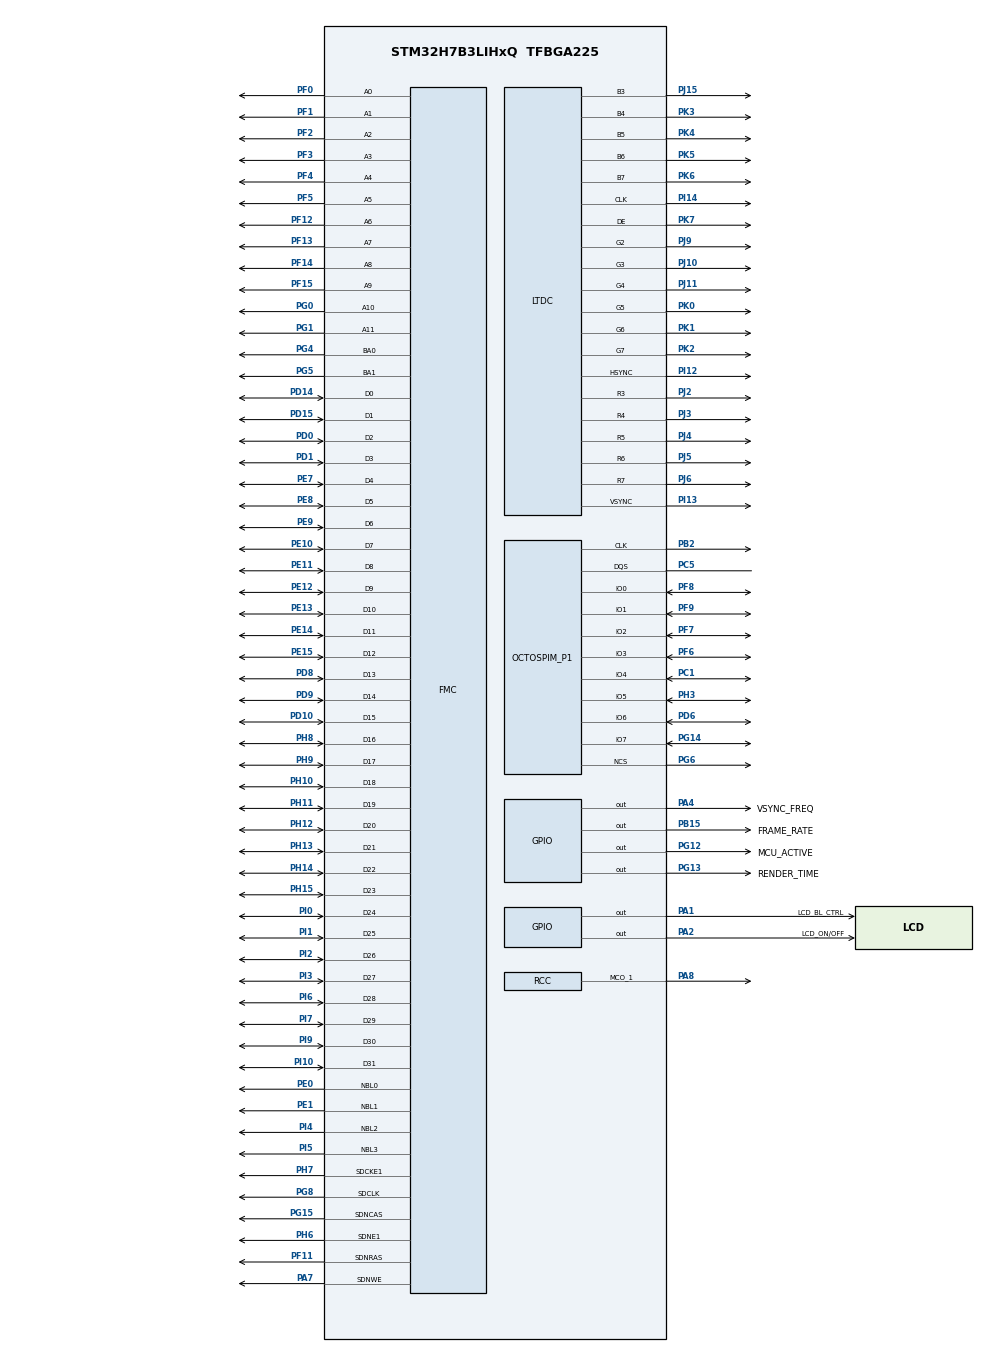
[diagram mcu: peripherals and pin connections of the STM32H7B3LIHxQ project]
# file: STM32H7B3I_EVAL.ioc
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CORTEX_M7.AccessPermission-Cortex_Memory_Protection_Unit_Region0_Settings=MPU_REGION_FULL_ACCESS
CORTEX_M7.AccessPermission-Cortex_Memory_Protection_Unit_Region1_Settings=MPU_REGION_NO_ACCESS
CORTEX_M7.AccessPermission-Cortex_Memory_Protection_Unit_Region2_Settings=MPU_REGION_FULL_ACCESS
CORTEX_M7.AccessPermission-Cortex_Memory_Protection_Unit_Region3_Settings=MPU_REGION_NO_ACCESS
CORTEX_M7.AccessPermission-Cortex_Memory_Protection_Unit_Region4_Settings=MPU_REGION_FULL_ACCESS
CORTEX_M7.BaseAddress-Cortex_Memory_Protection_Unit_Region0_Settings=0x24000000
CORTEX_M7.BaseAddress-Cortex_Memory_Protection_Unit_Region1_Settings=0x90000000
CORTEX_M7.BaseAddress-Cortex_Memory_Protection_Unit_Region2_Settings=0x90000000
CORTEX_M7.BaseAddress-Cortex_Memory_Protection_Unit_Region3_Settings=0xD0000000
CORTEX_M7.BaseAddress-Cortex_Memory_Protection_Unit_Region4_Settings=0xD0000000
CORTEX_M7.CPU_DCache=Enabled
CORTEX_M7.CPU_ICache=Enabled
CORTEX_M7.DisableExec-Cortex_Memory_Protection_Unit_Region0_Settings=MPU_INSTRUCTION_ACCESS_DISABLE
CORTEX_M7.DisableExec-Cortex_Memory_Protection_Unit_Region1_Settings=MPU_INSTRUCTION_ACCESS_DISABLE
CORTEX_M7.DisableExec-Cortex_Memory_Protection_Unit_Region2_Settings=MPU_INSTRUCTION_ACCESS_DISABLE
CORTEX_M7.DisableExec-Cortex_Memory_Protection_Unit_Region3_Settings=MPU_INSTRUCTION_ACCESS_DISABLE
CORTEX_M7.DisableExec-Cortex_Memory_Protection_Unit_Region4_Settings=MPU_INSTRUCTION_ACCESS_DISABLE
CORTEX_M7.Enable-Cortex_Memory_Protection_Unit_Region0_Settings=MPU_REGION_ENABLE
CORTEX_M7.Enable-Cortex_Memory_Protection_Unit_Region1_Settings=MPU_REGION_ENABLE
CORTEX_M7.Enable-Cortex_Memory_Protection_Unit_Region2_Settings=MPU_REGION_ENABLE
CORTEX_M7.Enable-Cortex_Memory_Protection_Unit_Region3_Settings=MPU_REGION_ENABLE
CORTEX_M7.Enable-Cortex_Memory_Protection_Unit_Region4_Settings=MPU_REGION_ENABLE
CORTEX_M7.IsBufferable-Cortex_Memory_Protection_Unit_Region2_Settings=MPU_ACCESS_NOT_BUFFERABLE
CORTEX_M7.IsBufferable-Cortex_Memory_Protection_Unit_Region4_Settings=MPU_ACCESS_BUFFERABLE
CORTEX_M7.IsCacheable-Cortex_Memory_Protection_Unit_Region0_Settings=MPU_ACCESS_CACHEABLE
CORTEX_M7.IsCacheable-Cortex_Memory_Protection_Unit_Region2_Settings=MPU_ACCESS_CACHEABLE
CORTEX_M7.IsCacheable-Cortex_Memory_Protection_Unit_Region4_Settings=MPU_ACCESS_CACHEABLE
CORTEX_M7.MPU_Control=MPU_PRIVILEGED_DEFAULT
CORTEX_M7.Size-Cortex_Memory_Protection_Unit_Region0_Settings=MPU_REGION_SIZE_1MB
CORTEX_M7.Size-Cortex_Memory_Protection_Unit_Region1_Settings=MPU_REGION_SIZE_512MB
CORTEX_M7.Size-Cortex_Memory_Protection_Unit_Region2_Settings=MPU_REGION_SIZE_64MB
CORTEX_M7.Size-Cortex_Memory_Protection_Unit_Region3_Settings=MPU_REGION_SIZE_512MB
CORTEX_M7.Size-Cortex_Memory_Protection_Unit_Region4_Settings=MPU_REGION_SIZE_32MB
DMA2D.ColorMode=DMA2D_OUTPUT_RGB565
DMA2D.Mode=DMA2D_R2M
FMC.CASLatency2=FMC_SDRAM_CAS_LATENCY_3
FMC.ColumnBitsNumber2=FMC_SDRAM_COLUMN_BITS_NUM_9
FMC.ExitSelfRefreshDelay2=7
FMC.LoadToActiveDelay2=2
FMC.RCDDelay2=2
FMC.RPDelay2=2
FMC.ReadBurst2=FMC_SDRAM_RBURST_ENABLE
FMC.ReadPipeDelay2=FMC_SDRAM_RPIPE_DELAY_2
FMC.RowCycleDelay2=7
FMC.SelfRefreshTime2=4
FMC.WriteRecoveryTime2=3
FREERTOS.Tasks01=defaultTask,24,128,StartDefaultTask,Default,NULL,Dynamic,NULL,NULL;TouchGFXTask,24,4096,TouchGFX_Task,As external,NULL,Dynamic,NULL,NULL
FREERTOS.configTOTAL_HEAP_SIZE=32768
FREERTOS.configUSE_APPLICATION_TASK_TAG=1
FREERTOS.configUSE_IDLE_HOOK=1
FREERTOS.configUSE_PREEMPTION=1
LTDC.ActiveW=800
LTDC.Alpha_L0=255
LTDC.BlendingFactor1_L0=LTDC_BLENDING_FACTOR1_CA
LTDC.BlendingFactor2_L0=LTDC_BLENDING_FACTOR2_CA
LTDC.Blue_L0=0
LTDC.HBP=2
LTDC.HFP=210
LTDC.HSync=46
LTDC.ImageHeight_L0=480
LTDC.ImageWidth_L0=800
LTDC.Layers=0
LTDC.PixelFormat_L0=LTDC_PIXEL_FORMAT_RGB565
LTDC.VBP=2
LTDC.VFP=22
LTDC.VSync=23
LTDC.WindowX1_L0=800
LTDC.WindowY1_L0=480
Mcu.Family=STM32H7
Mcu.Name=STM32H7B3LIHxQ
Mcu.Package=TFBGA225
NVIC.DMA2D_IRQn=true\:9\:0\:true\:false\:true\:true\:true\:true\:true
NVIC.LTDC_IRQn=true\:9\:0\:true\:false\:true\:true\:true\:true\:true
NVIC.OCTOSPI1_IRQn=true\:6\:0\:true\:false\:true\:true\:true\:true\:true
NVIC.PriorityGroup=NVIC_PRIORITYGROUP_4
NVIC.TIM6_DAC_IRQn=true\:0\:0\:false\:false\:true\:false\:false\:true\:true
NVIC.TimeBase=TIM6_DAC_IRQn
NVIC.TimeBaseIP=TIM6
OCTOSPI1.ChipSelectBoundary=0
OCTOSPI1.ChipSelectHighTime=2
OCTOSPI1.ClockPrescaler=3
OCTOSPI1.DelayHoldQuarterCycle=HAL_OSPI_DHQC_ENABLE
OCTOSPI1.FifoThreshold=4
OCTOSPI1.MemoryType=HAL_OSPI_MEMTYPE_MACRONIX
PA1.GPIO_Label=LCD_BL_CTRL
PA1.Signal=GPIO_Output
PA2.GPIO_Label=LCD_ON/OFF
PA2.Signal=GPIO_Output
PA4.GPIO_Label=VSYNC_FREQ
PA4.GPIO_Speed=GPIO_SPEED_FREQ_VERY_HIGH
PA4.Signal=GPIO_Output
PA7.Signal=FMC_SDNWE
PA8.Mode=Clock-out-1
PA8.Signal=RCC_MCO_1
PB15.GPIO_Label=FRAME_RATE
PB15.GPIO_Speed=GPIO_SPEED_FREQ_VERY_HIGH
PB15.Signal=GPIO_Output
PB2.Mode=O1_P1_CLK
PB2.Signal=OCTOSPIM_P1_CLK
PC1.Mode=OCTOSPI1_IOH_Port1H
PC1.Signal=OCTOSPIM_P1_IO4
PC5.Mode=OCTOSPI1_Port1_DQS
PC5.Signal=OCTOSPIM_P1_DQS
PD0.Signal=FMC_D2_DA2
PD1.Signal=FMC_D3_DA3
PD10.Signal=FMC_D15_DA15
PD14.Signal=FMC_D0_DA0
PD15.Signal=FMC_D1_DA1
PD6.Mode=OCTOSPI1_IOH_Port1H
PD6.Signal=OCTOSPIM_P1_IO6
PD8.Signal=FMC_D13_DA13
PD9.Signal=FMC_D14_DA14
PE0.Signal=FMC_NBL0
PE1.Signal=FMC_NBL1
PE10.Signal=FMC_D7_DA7
PE11.Signal=FMC_D8_DA8
PE12.Signal=FMC_D9_DA9
PE13.Signal=FMC_D10_DA10
PE14.Signal=FMC_D11_DA11
PE15.Signal=FMC_D12_DA12
PE7.Signal=FMC_D4_DA4
PE8.Signal=FMC_D5_DA5
PE9.Signal=FMC_D6_DA6
PF0.Signal=FMC_A0
PF1.Signal=FMC_A1
PF11.Signal=FMC_SDNRAS
PF12.Signal=FMC_A6
PF13.Signal=FMC_A7
PF14.Signal=FMC_A8
PF15.Signal=FMC_A9
PF2.Signal=FMC_A2
PF3.Signal=FMC_A3
PF4.Signal=FMC_A4
PF5.Signal=FMC_A5
PF6.Mode=OCTOSPI1_IOL_Port1L
PF6.Signal=OCTOSPIM_P1_IO3
PF7.Mode=OCTOSPI1_IOL_Port1L
PF7.Signal=OCTOSPIM_P1_IO2
PF8.Mode=OCTOSPI1_IOL_Port1L
PF8.Signal=OCTOSPIM_P1_IO0
PF9.Mode=OCTOSPI1_IOL_Port1L
PF9.Signal=OCTOSPIM_P1_IO1
PG0.Signal=FMC_A10
PG1.Signal=FMC_A11
PG12.GPIO_Label=MCU_ACTIVE
PG12.GPIO_Speed=GPIO_SPEED_FREQ_VERY_HIGH
PG12.Signal=GPIO_Output
PG13.GPIO_Label=RENDER_TIME
PG13.GPIO_Speed=GPIO_SPEED_FREQ_VERY_HIGH
PG13.Signal=GPIO_Output
PG14.Mode=OCTOSPI1_IOH_Port1H
PG14.Signal=OCTOSPIM_P1_IO7
PG15.Signal=FMC_SDNCAS
PG4.Signal=FMC_A14_BA0
PG5.Signal=FMC_A15_BA1
PG6.Mode=OCTOSPI1_Port1_NCS
PG6.Signal=OCTOSPIM_P1_NCS
PG8.Signal=FMC_SDCLK
PH0-OSC_IN.Mode=HSE-External-Oscillator
PH0-OSC_IN.Signal=RCC_OSC_IN
PH1-OSC_OUT.Mode=HSE-External-Oscillator
PH1-OSC_OUT.Signal=RCC_OSC_OUT
PH10.Signal=FMC_D18
PH11.Signal=FMC_D19
PH12.Signal=FMC_D20
PH13.Signal=FMC_D21
PH14.Signal=FMC_D22
PH15.Signal=FMC_D23
PH3.Mode=OCTOSPI1_IOH_Port1H
PH3.Signal=OCTOSPIM_P1_IO5
PH6.Mode=SdramChipSelect2_2
PH6.Signal=FMC_SDNE1
PH7.Mode=SdramChipSelect2_2
PH7.Signal=FMC_SDCKE1
PH8.Signal=FMC_D16
PH9.Signal=FMC_D17
PI0.Signal=FMC_D24
PI1.Signal=FMC_D25
PI10.Signal=FMC_D31
PI12.GPIO_Speed=GPIO_SPEED_FREQ_VERY_HIGH
PI12.Mode=RGB565
PI12.Signal=LTDC_HSYNC
PI13.GPIO_Speed=GPIO_SPEED_FREQ_VERY_HIGH
PI13.Mode=RGB565
PI13.Signal=LTDC_VSYNC
PI14.GPIO_Speed=GPIO_SPEED_FREQ_VERY_HIGH
PI14.Mode=RGB565
PI14.Signal=LTDC_CLK
PI15.GPIO_Speed=GPIO_SPEED_FREQ_HIGH
PI15.Signal=LTDC_R0
PI2.Signal=FMC_D26
PI3.Signal=FMC_D27
PI4.Signal=FMC_NBL2
PI5.Signal=FMC_NBL3
PI6.Signal=FMC_D28
PI7.Signal=FMC_D29
PI9.Signal=FMC_D30
PJ10.GPIO_Speed=GPIO_SPEED_FREQ_VERY_HIGH
PJ10.Mode=RGB565
PJ10.Signal=LTDC_G3
PJ11.GPIO_Speed=GPIO_SPEED_FREQ_VERY_HIGH
PJ11.Mode=RGB565
PJ11.Signal=LTDC_G4
PJ15.GPIO_Speed=GPIO_SPEED_FREQ_VERY_HIGH
PJ15.Mode=RGB565
PJ15.Signal=LTDC_B3
PJ2.GPIO_Speed=GPIO_SPEED_FREQ_VERY_HIGH
PJ2.Mode=RGB565
PJ2.Signal=LTDC_R3
PJ3.GPIO_Speed=GPIO_SPEED_FREQ_VERY_HIGH
PJ3.Mode=RGB565
PJ3.Signal=LTDC_R4
PJ4.GPIO_Speed=GPIO_SPEED_FREQ_VERY_HIGH
PJ4.Mode=RGB565
PJ4.Signal=LTDC_R5
PJ5.GPIO_Speed=GPIO_SPEED_FREQ_VERY_HIGH
PJ5.Mode=RGB565
PJ5.Signal=LTDC_R6
PJ6.GPIO_Speed=GPIO_SPEED_FREQ_VERY_HIGH
PJ6.Mode=RGB565
PJ6.Signal=LTDC_R7
PJ9.GPIO_Speed=GPIO_SPEED_FREQ_VERY_HIGH
PJ9.Mode=RGB565
PJ9.Signal=LTDC_G2
PK0.GPIO_Speed=GPIO_SPEED_FREQ_VERY_HIGH
PK0.Mode=RGB565
PK0.Signal=LTDC_G5
PK1.GPIO_Speed=GPIO_SPEED_FREQ_VERY_HIGH
PK1.Mode=RGB565
PK1.Signal=LTDC_G6
PK2.GPIO_Speed=GPIO_SPEED_FREQ_VERY_HIGH
PK2.Mode=RGB565
PK2.Signal=LTDC_G7
PK3.GPIO_Speed=GPIO_SPEED_FREQ_VERY_HIGH
PK3.Mode=RGB565
PK3.Signal=LTDC_B4
PK4.GPIO_Speed=GPIO_SPEED_FREQ_VERY_HIGH
PK4.Mode=RGB565
PK4.Signal=LTDC_B5
PK5.GPIO_Speed=GPIO_SPEED_FREQ_VERY_HIGH
PK5.Mode=RGB565
PK5.Signal=LTDC_B6
PK6.GPIO_Speed=GPIO_SPEED_FREQ_VERY_HIGH
PK6.Mode=RGB565
PK6.Signal=LTDC_B7
PK7.GPIO_Speed=GPIO_SPEED_FREQ_VERY_HIGH
PK7.Mode=RGB565
PK7.Signal=LTDC_DE
ProjectManager.HeapSize=0x1000
ProjectManager.StackSize=0x1000
ProjectManager.TargetToolchain=STM32CubeIDE
RCC.ADCFreq_Value=200000000
RCC.APB1Freq_Value=140000000
RCC.APB2Freq_Value=140000000
RCC.APB3Freq_Value=140000000
RCC.APB4Freq_Value=140000000
RCC.CDPPRE=RCC_APB3_DIV2
RCC.CDPPRE1=RCC_APB1_DIV2
RCC.CDPPRE2=RCC_APB2_DIV2
RCC.CKPERSourceSelection=RCC_CLKPSOURCE_HSE
RCC.CortexFreq_Value=280000000
RCC.DIVM1=12
RCC.DIVM2=12
RCC.DIVM3=24
RCC.DIVN1=280
RCC.DIVN2=200
RCC.DIVN3=288
RCC.DIVR3=9
RCC.FLatency=FLASH_LATENCY_6
RCC.HCLKFreq_Value=280000000
RCC.PLL2FRACN=0
RCC.PLL3FRACN=0
RCC.PLLFRACN=0
RCC.PLLSourceVirtual=RCC_PLLSOURCE_HSE
RCC.RCC_MCO1Source=RCC_MCO1SOURCE_HSE
RCC.SRDPPRE=RCC_APB4_DIV2
RCC.SYSCLKFreq_VALUE=280000000
RCC.SYSCLKSource=RCC_SYSCLKSOURCE_PLLCLK
RCC.SupplySource=PWR_DIRECT_SMPS_SUPPLY
RCC.USBFreq_Value=280000000
SH.FMC_A0.0=FMC_A0,12b-sda2
SH.FMC_A1.0=FMC_A1,12b-sda2
SH.FMC_A10.0=FMC_A10,12b-sda2
SH.FMC_A11.0=FMC_A11,12b-sda2
SH.FMC_A14_BA0.0=FMC_A14
SH.FMC_A14_BA0.1=FMC_BA0,FourSdramBanks2
SH.FMC_A15_BA1.0=FMC_BA1,FourSdramBanks2
SH.FMC_A2.0=FMC_A2,12b-sda2
SH.FMC_A3.0=FMC_A3,12b-sda2
SH.FMC_A4.0=FMC_A4,12b-sda2
SH.FMC_A5.0=FMC_A5,12b-sda2
SH.FMC_A6.0=FMC_A6,12b-sda2
SH.FMC_A7.0=FMC_A7,12b-sda2
SH.FMC_A8.0=FMC_A8,12b-sda2
SH.FMC_A9.0=FMC_A9,12b-sda2
SH.FMC_D0_DA0.0=FMC_D0,sd-32b-d2
SH.FMC_D10_DA10.0=FMC_D10,sd-32b-d2
SH.FMC_D11_DA11.0=FMC_D11,sd-32b-d2
SH.FMC_D12_DA12.0=FMC_D12,sd-32b-d2
SH.FMC_D13_DA13.0=FMC_D13,sd-32b-d2
SH.FMC_D14_DA14.0=FMC_D14,sd-32b-d2
SH.FMC_D15_DA15.0=FMC_D15,sd-32b-d2
SH.FMC_D16.0=FMC_D16,sd-32b-d2
SH.FMC_D17.0=FMC_D17,sd-32b-d2
SH.FMC_D18.0=FMC_D18,sd-32b-d2
SH.FMC_D19.0=FMC_D19,sd-32b-d2
SH.FMC_D1_DA1.0=FMC_D1,sd-32b-d2
SH.FMC_D20.0=FMC_D20,sd-32b-d2
SH.FMC_D21.0=FMC_D21,sd-32b-d2
SH.FMC_D22.0=FMC_D22,sd-32b-d2
SH.FMC_D23.0=FMC_D23,sd-32b-d2
SH.FMC_D24.0=FMC_D24,sd-32b-d2
SH.FMC_D25.0=FMC_D25,sd-32b-d2
SH.FMC_D26.0=FMC_D26,sd-32b-d2
SH.FMC_D27.0=FMC_D27,sd-32b-d2
SH.FMC_D28.0=FMC_D28,sd-32b-d2
SH.FMC_D29.0=FMC_D29,sd-32b-d2
SH.FMC_D2_DA2.0=FMC_D2,sd-32b-d2
SH.FMC_D30.0=FMC_D30,sd-32b-d2
SH.FMC_D31.0=FMC_D31,sd-32b-d2
SH.FMC_D3_DA3.0=FMC_D3,sd-32b-d2
SH.FMC_D4_DA4.0=FMC_D4,sd-32b-d2
SH.FMC_D5_DA5.0=FMC_D5,sd-32b-d2
SH.FMC_D6_DA6.0=FMC_D6,sd-32b-d2
SH.FMC_D7_DA7.0=FMC_D7,sd-32b-d2
SH.FMC_D8_DA8.0=FMC_D8,sd-32b-d2
SH.FMC_D9_DA9.0=FMC_D9,sd-32b-d2
SH.FMC_NBL0.0=FMC_NBL0,Sd4ByteEnable2
SH.FMC_NBL1.0=FMC_NBL1,Sd4ByteEnable2
SH.FMC_NBL2.0=FMC_NBL2,Sd4ByteEnable2
SH.FMC_NBL3.0=FMC_NBL3,Sd4ByteEnable2
SH.FMC_SDCLK.0=FMC_SDCLK,12b-sda2
SH.FMC_SDNCAS.0=FMC_SDNCAS,12b-sda2
SH.FMC_SDNRAS.0=FMC_SDNRAS,12b-sda2
SH.FMC_SDNWE.0=FMC_SDNWE,12b-sda2
STMicroelectronics.X-CUBE-TOUCHGFX.4.25.0.ApplicationCcGraphicsJjApplication=TouchGFXOoGenerator
STMicroelectronics.X-CUBE-TOUCHGFX.4.25.0.tgfx_address1=0xD0000000
STMicroelectronics.X-CUBE-TOUCHGFX.4.25.0.tgfx_address2=0xD00C0000
STMicroelectronics.X-CUBE-TOUCHGFX.4.25.0.tgfx_buffering_strategy=Double
STMicroelectronics.X-CUBE-TOUCHGFX.4.25.0.tgfx_display_interface=disp_ltdc
STMicroelectronics.X-CUBE-TOUCHGFX.4.25.0.tgfx_hardware_accelerator=dma_2d
STMicroelectronics.X-CUBE-TOUCHGFX.4.25.0.tgfx_location=Allocate
STMicroelectronics.X-CUBE-TOUCHGFX.4.25.0.tgfx_vector_fonts=Enabled
STMicroelectronics.X-CUBE-TOUCHGFX.4.25.0.tgfx_vector_rendering=Software
STMicroelectronics.X-CUBE-TOUCHGFX.4.25.0.tgfx_vsync=vsync_ltdc
VP_CRC_VS_CRC.Mode=CRC_Activate
VP_DMA2D_VS_DMA2D.Mode=DMA2D_Activate
VP_FREERTOS_VS_CMSIS_V2.Mode=CMSIS_V2
VP_OCTOSPI1_VS_octo.Mode=octo_mode
VP_STMicroelectronics.X-CUBE-TOUCHGFX_VS_GraphicsJjApplication_4.25.0.Mode=GraphicsJjApplication
VP_SYS_VS_tim6.Mode=TIM6
board=custom

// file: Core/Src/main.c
/* USER CODE BEGIN Header */
/**
  ******************************************************************************
  * @file           : main.c
  * @brief          : Main program body
  ******************************************************************************
  * @attention
  *
  * <h2><center>&copy; Copyright (c) 2021 STMicroelectronics.
  * All rights reserved.</center></h2>
  *
  * This software component is licensed by ST under Ultimate Liberty license
  * SLA0044, the "License"; You may not use this file except in compliance with
  * the License. You may obtain a copy of the License at:
  *                             www.st.com/SLA0044
  *
  ******************************************************************************
  */
/* USER CODE END Header */
#include "main.h"
#include "cmsis_os.h"
#include "app_touchgfx.h"

CRC_HandleTypeDef hcrc;

DMA2D_HandleTypeDef hdma2d;

LTDC_HandleTypeDef hltdc;

OSPI_HandleTypeDef hospi1;

SDRAM_HandleTypeDef hsdram2;

/* Definitions for defaultTask */
osThreadId_t defaultTaskHandle;
const osThreadAttr_t defaultTask_attributes = {
  .name = "defaultTask",
  .stack_size = 128 * 4,
  .priority = (osPriority_t) osPriorityNormal,
};
/* Definitions for TouchGFXTask */
osThreadId_t TouchGFXTaskHandle;
const osThreadAttr_t TouchGFXTask_attributes = {
  .name = "TouchGFXTask",
  .stack_size = 4096 * 4,
  .priority = (osPriority_t) osPriorityNormal,
};

void SystemClock_Config(void);
static void MPU_Config(void);
static void MX_GPIO_Init(void);
static void MX_CRC_Init(void);
static void MX_DMA2D_Init(void);
static void MX_LTDC_Init(void);
static void MX_OCTOSPI1_Init(void);
static void MX_FMC_Init(void);
void StartDefaultTask(void *argument);
extern void TouchGFX_Task(void *argument);

int main(void)
{

  /* MPU Configuration--------------------------------------------------------*/
  MPU_Config();

  /* Enable the CPU Cache */

  /* Enable I-Cache---------------------------------------------------------*/
  SCB_EnableICache();

  /* Enable D-Cache---------------------------------------------------------*/
  SCB_EnableDCache();

  /* MCU Configuration--------------------------------------------------------*/

  /* Reset of all peripherals, Initializes the Flash interface and the Systick. */
  HAL_Init();

  /* Configure the system clock */
  SystemClock_Config();

  /* Initialize all configured peripherals */
  MX_GPIO_Init();
  MX_CRC_Init();
  MX_DMA2D_Init();
  MX_LTDC_Init();
  MX_OCTOSPI1_Init();
  MX_FMC_Init();
  MX_TouchGFX_Init();
  /* Call PreOsInit function */
  MX_TouchGFX_PreOSInit();

  /* Init scheduler */
  osKernelInitialize();

  /* Create the thread(s) */
  /* creation of defaultTask */
  defaultTaskHandle = osThreadNew(StartDefaultTask, NULL, &defaultTask_attributes);

  /* creation of TouchGFXTask */
  TouchGFXTaskHandle = osThreadNew(TouchGFX_Task, NULL, &TouchGFXTask_attributes);

  /* Start scheduler */
  osKernelStart();

  /* We should never get here as control is now taken by the scheduler */

  /* Infinite loop */
  while (1)
  {

  }
}

void SystemClock_Config(void)
{
  RCC_OscInitTypeDef RCC_OscInitStruct = {0};
  RCC_ClkInitTypeDef RCC_ClkInitStruct = {0};

  /*AXI clock gating */
  RCC->CKGAENR = 0xFFFFFFFF;

  /** Supply configuration update enable
  */
  HAL_PWREx_ConfigSupply(PWR_DIRECT_SMPS_SUPPLY);

  /** Configure the main internal regulator output voltage
  */
  __HAL_PWR_VOLTAGESCALING_CONFIG(PWR_REGULATOR_VOLTAGE_SCALE0);

  while(!__HAL_PWR_GET_FLAG(PWR_FLAG_VOSRDY)) {}

  /** Initializes the RCC Oscillators according to the specified parameters
  * in the RCC_OscInitTypeDef structure.
  */
  RCC_OscInitStruct.OscillatorType = RCC_OSCILLATORTYPE_HSE;
  RCC_OscInitStruct.HSEState = RCC_HSE_ON;
  RCC_OscInitStruct.PLL.PLLState = RCC_PLL_ON;
  RCC_OscInitStruct.PLL.PLLSource = RCC_PLLSOURCE_HSE;
  RCC_OscInitStruct.PLL.PLLM = 12;
  RCC_OscInitStruct.PLL.PLLN = 280;
  RCC_OscInitStruct.PLL.PLLP = 2;
  RCC_OscInitStruct.PLL.PLLQ = 2;
  RCC_OscInitStruct.PLL.PLLR = 2;
  RCC_OscInitStruct.PLL.PLLRGE = RCC_PLL1VCIRANGE_1;
  RCC_OscInitStruct.PLL.PLLVCOSEL = RCC_PLL1VCOWIDE;
  RCC_OscInitStruct.PLL.PLLFRACN = 0;
  if (HAL_RCC_OscConfig(&RCC_OscInitStruct) != HAL_OK)
  {
    Error_Handler();
  }

  /** Initializes the CPU, AHB and APB buses clocks
  */
  RCC_ClkInitStruct.ClockType = RCC_CLOCKTYPE_HCLK|RCC_CLOCKTYPE_SYSCLK
                              |RCC_CLOCKTYPE_PCLK1|RCC_CLOCKTYPE_PCLK2
                              |RCC_CLOCKTYPE_D3PCLK1|RCC_CLOCKTYPE_D1PCLK1;
  RCC_ClkInitStruct.SYSCLKSource = RCC_SYSCLKSOURCE_PLLCLK;
  RCC_ClkInitStruct.SYSCLKDivider = RCC_SYSCLK_DIV1;
  RCC_ClkInitStruct.AHBCLKDivider = RCC_HCLK_DIV1;
  RCC_ClkInitStruct.APB3CLKDivider = RCC_APB3_DIV2;
  RCC_ClkInitStruct.APB1CLKDivider = RCC_APB1_DIV2;
  RCC_ClkInitStruct.APB2CLKDivider = RCC_APB2_DIV2;
  RCC_ClkInitStruct.APB4CLKDivider = RCC_APB4_DIV2;

  if (HAL_RCC_ClockConfig(&RCC_ClkInitStruct, FLASH_LATENCY_6) != HAL_OK)
  {
    Error_Handler();
  }
  HAL_RCC_MCOConfig(RCC_MCO1, RCC_MCO1SOURCE_HSE, RCC_MCODIV_1);
}

static void MX_CRC_Init(void)
{

  hcrc.Instance = CRC;
  hcrc.Init.DefaultPolynomialUse = DEFAULT_POLYNOMIAL_ENABLE;
  hcrc.Init.DefaultInitValueUse = DEFAULT_INIT_VALUE_ENABLE;
  hcrc.Init.InputDataInversionMode = CRC_INPUTDATA_INVERSION_NONE;
  hcrc.Init.OutputDataInversionMode = CRC_OUTPUTDATA_INVERSION_DISABLE;
  hcrc.InputDataFormat = CRC_INPUTDATA_FORMAT_BYTES;
  if (HAL_CRC_Init(&hcrc) != HAL_OK)
  {
    Error_Handler();
  }

}

static void MX_DMA2D_Init(void)
{

  hdma2d.Instance = DMA2D;
  hdma2d.Init.Mode = DMA2D_R2M;
  hdma2d.Init.ColorMode = DMA2D_OUTPUT_RGB565;
  hdma2d.Init.OutputOffset = 0;
  if (HAL_DMA2D_Init(&hdma2d) != HAL_OK)
  {
    Error_Handler();
  }

}

static void MX_LTDC_Init(void)
{

  LTDC_LayerCfgTypeDef pLayerCfg = {0};

  hltdc.Instance = LTDC;
  hltdc.Init.HSPolarity = LTDC_HSPOLARITY_AL;
  hltdc.Init.VSPolarity = LTDC_VSPOLARITY_AL;
  hltdc.Init.DEPolarity = LTDC_DEPOLARITY_AL;
  hltdc.Init.PCPolarity = LTDC_PCPOLARITY_IPC;
  hltdc.Init.HorizontalSync = 45;
  hltdc.Init.VerticalSync = 22;
  hltdc.Init.AccumulatedHBP = 47;
  hltdc.Init.AccumulatedVBP = 24;
  hltdc.Init.AccumulatedActiveW = 847;
  hltdc.Init.AccumulatedActiveH = 504;
  hltdc.Init.TotalWidth = 1057;
  hltdc.Init.TotalHeigh = 526;
  hltdc.Init.Backcolor.Blue = 0;
  hltdc.Init.Backcolor.Green = 0;
  hltdc.Init.Backcolor.Red = 0;
  if (HAL_LTDC_Init(&hltdc) != HAL_OK)
  {
    Error_Handler();
  }
  pLayerCfg.WindowX0 = 0;
  pLayerCfg.WindowX1 = 800;
  pLayerCfg.WindowY0 = 0;
  pLayerCfg.WindowY1 = 480;
  pLayerCfg.PixelFormat = LTDC_PIXEL_FORMAT_RGB565;
  pLayerCfg.Alpha = 255;
  pLayerCfg.Alpha0 = 0;
  pLayerCfg.BlendingFactor1 = LTDC_BLENDING_FACTOR1_CA;
  pLayerCfg.BlendingFactor2 = LTDC_BLENDING_FACTOR2_CA;
  pLayerCfg.FBStartAdress = 0;
  pLayerCfg.ImageWidth = 800;
  pLayerCfg.ImageHeight = 480;
  pLayerCfg.Backcolor.Blue = 0;
  pLayerCfg.Backcolor.Green = 0;
  pLayerCfg.Backcolor.Red = 0;
  if (HAL_LTDC_ConfigLayer(&hltdc, &pLayerCfg, 0) != HAL_OK)
  {
    Error_Handler();
  }

}

static void MX_OCTOSPI1_Init(void)
{

  OSPIM_CfgTypeDef sOspiManagerCfg = {0};

  /* OCTOSPI1 parameter configuration*/
  hospi1.Instance = OCTOSPI1;
  hospi1.Init.FifoThreshold = 4;
  hospi1.Init.DualQuad = HAL_OSPI_DUALQUAD_DISABLE;
  hospi1.Init.MemoryType = HAL_OSPI_MEMTYPE_MACRONIX;
  hospi1.Init.DeviceSize = 32;
  hospi1.Init.ChipSelectHighTime = 2;
  hospi1.Init.FreeRunningClock = HAL_OSPI_FREERUNCLK_DISABLE;
  hospi1.Init.ClockMode = HAL_OSPI_CLOCK_MODE_0;
  hospi1.Init.WrapSize = HAL_OSPI_WRAP_NOT_SUPPORTED;
  hospi1.Init.ClockPrescaler = 3;
  hospi1.Init.SampleShifting = HAL_OSPI_SAMPLE_SHIFTING_NONE;
  hospi1.Init.DelayHoldQuarterCycle = HAL_OSPI_DHQC_ENABLE;
  hospi1.Init.ChipSelectBoundary = 0;
  hospi1.Init.DelayBlockBypass = HAL_OSPI_DELAY_BLOCK_BYPASSED;
  hospi1.Init.MaxTran = 0;
  hospi1.Init.Refresh = 0;
  if (HAL_OSPI_Init(&hospi1) != HAL_OK)
  {
    Error_Handler();
  }
  sOspiManagerCfg.ClkPort = 1;
  sOspiManagerCfg.DQSPort = 1;
  sOspiManagerCfg.NCSPort = 1;
  sOspiManagerCfg.IOLowPort = HAL_OSPIM_IOPORT_1_LOW;
  sOspiManagerCfg.IOHighPort = HAL_OSPIM_IOPORT_1_HIGH;
  if (HAL_OSPIM_Config(&hospi1, &sOspiManagerCfg, HAL_OSPI_TIMEOUT_DEFAULT_VALUE) != HAL_OK)
  {
    Error_Handler();
  }
  /* USER CODE BEGIN OCTOSPI1_Init 2 */
  int32_t RetVal = 0;
  BSP_OSPI_NOR_Init_t Flash;

  if (HAL_OSPI_DeInit(&hospi1) != HAL_OK)
  {
    Error_Handler();
  }
  BSP_OSPI_NOR_DeInit(0);

  Flash.InterfaceMode = BSP_OSPI_NOR_OPI_MODE;
  Flash.TransferRate  = BSP_OSPI_NOR_DTR_TRANSFER;
  RetVal = BSP_OSPI_NOR_Init(0, &Flash);
  if (RetVal != BSP_ERROR_NONE)
  {
    Error_Handler();
  }
  RetVal = BSP_OSPI_NOR_EnableMemoryMappedMode(0);
  if (RetVal != BSP_ERROR_NONE)
  {
    Error_Handler();
  }
  /* USER CODE END OCTOSPI1_Init 2 */

}

/* FMC initialization function */
static void MX_FMC_Init(void)
{

  FMC_SDRAM_TimingTypeDef SdramTiming = {0};

  /** Perform the SDRAM2 memory initialization sequence
  */
  hsdram2.Instance = FMC_SDRAM_DEVICE;
  /* hsdram2.Init */
  hsdram2.Init.SDBank = FMC_SDRAM_BANK2;
  hsdram2.Init.ColumnBitsNumber = FMC_SDRAM_COLUMN_BITS_NUM_9;
  hsdram2.Init.RowBitsNumber = FMC_SDRAM_ROW_BITS_NUM_12;
  hsdram2.Init.MemoryDataWidth = FMC_SDRAM_MEM_BUS_WIDTH_32;
  hsdram2.Init.InternalBankNumber = FMC_SDRAM_INTERN_BANKS_NUM_4;
  hsdram2.Init.CASLatency = FMC_SDRAM_CAS_LATENCY_3;
  hsdram2.Init.WriteProtection = FMC_SDRAM_WRITE_PROTECTION_DISABLE;
  hsdram2.Init.SDClockPeriod = FMC_SDRAM_CLOCK_DISABLE;
  hsdram2.Init.ReadBurst = FMC_SDRAM_RBURST_ENABLE;
  hsdram2.Init.ReadPipeDelay = FMC_SDRAM_RPIPE_DELAY_2;
  /* SdramTiming */
  SdramTiming.LoadToActiveDelay = 2;
  SdramTiming.ExitSelfRefreshDelay = 7;
  SdramTiming.SelfRefreshTime = 4;
  SdramTiming.RowCycleDelay = 7;
  SdramTiming.WriteRecoveryTime = 3;
  SdramTiming.RPDelay = 2;
  SdramTiming.RCDDelay = 2;

  if (HAL_SDRAM_Init(&hsdram2, &SdramTiming) != HAL_OK)
  {
    Error_Handler( );
  }

  /* USER CODE BEGIN FMC_Init 2 */
  if (HAL_SDRAM_DeInit(&hsdram2) != HAL_OK)
  {
    Error_Handler( );
  }

  BSP_SDRAM_DeInit(0);
  if (BSP_SDRAM_Init(0) != BSP_ERROR_NONE)
  {
    Error_Handler();
  }
  /* USER CODE END FMC_Init 2 */
}

static void MX_GPIO_Init(void)
{
  GPIO_InitTypeDef GPIO_InitStruct = {0};

  /* GPIO Ports Clock Enable */
  __HAL_RCC_GPIOI_CLK_ENABLE();
  __HAL_RCC_GPIOG_CLK_ENABLE();
  __HAL_RCC_GPIOK_CLK_ENABLE();
  __HAL_RCC_GPIOD_CLK_ENABLE();
  __HAL_RCC_GPIOE_CLK_ENABLE();
  __HAL_RCC_GPIOJ_CLK_ENABLE();
  __HAL_RCC_GPIOH_CLK_ENABLE();
  __HAL_RCC_GPIOF_CLK_ENABLE();
  __HAL_RCC_GPIOA_CLK_ENABLE();
  __HAL_RCC_GPIOC_CLK_ENABLE();
  __HAL_RCC_GPIOB_CLK_ENABLE();

  /*Configure GPIO pin Output Level */
  HAL_GPIO_WritePin(GPIOG, MCU_ACTIVE_Pin|RENDER_TIME_Pin, GPIO_PIN_RESET);

  /*Configure GPIO pin Output Level */
  HAL_GPIO_WritePin(GPIOA, VSYNC_FREQ_Pin|LCD_BL_CTRL_Pin|LCD_ON_OFF_Pin, GPIO_PIN_RESET);

  /*Configure GPIO pin Output Level */
  HAL_GPIO_WritePin(FRAME_RATE_GPIO_Port, FRAME_RATE_Pin, GPIO_PIN_RESET);

  /*Configure GPIO pins : MCU_ACTIVE_Pin RENDER_TIME_Pin */
  GPIO_InitStruct.Pin = MCU_ACTIVE_Pin|RENDER_TIME_Pin;
  GPIO_InitStruct.Mode = GPIO_MODE_OUTPUT_PP;
  GPIO_InitStruct.Pull = GPIO_NOPULL;
  GPIO_InitStruct.Speed = GPIO_SPEED_FREQ_VERY_HIGH;
  HAL_GPIO_Init(GPIOG, &GPIO_InitStruct);

  /*Configure GPIO pin : PA8 */
  GPIO_InitStruct.Pin = GPIO_PIN_8;
  GPIO_InitStruct.Mode = GPIO_MODE_AF_PP;
  GPIO_InitStruct.Pull = GPIO_NOPULL;
  GPIO_InitStruct.Speed = GPIO_SPEED_FREQ_LOW;
  GPIO_InitStruct.Alternate = GPIO_AF0_MCO;
  HAL_GPIO_Init(GPIOA, &GPIO_InitStruct);

  /*Configure GPIO pin : VSYNC_FREQ_Pin */
  GPIO_InitStruct.Pin = VSYNC_FREQ_Pin;
  GPIO_InitStruct.Mode = GPIO_MODE_OUTPUT_PP;
  GPIO_InitStruct.Pull = GPIO_NOPULL;
  GPIO_InitStruct.Speed = GPIO_SPEED_FREQ_VERY_HIGH;
  HAL_GPIO_Init(VSYNC_FREQ_GPIO_Port, &GPIO_InitStruct);

  /*Configure GPIO pin : FRAME_RATE_Pin */
  GPIO_InitStruct.Pin = FRAME_RATE_Pin;
  GPIO_InitStruct.Mode = GPIO_MODE_OUTPUT_PP;
  GPIO_InitStruct.Pull = GPIO_NOPULL;
  GPIO_InitStruct.Speed = GPIO_SPEED_FREQ_VERY_HIGH;
  HAL_GPIO_Init(FRAME_RATE_GPIO_Port, &GPIO_InitStruct);

  /*Configure GPIO pins : LCD_BL_CTRL_Pin LCD_ON_OFF_Pin */
  GPIO_InitStruct.Pin = LCD_BL_CTRL_Pin|LCD_ON_OFF_Pin;
  GPIO_InitStruct.Mode = GPIO_MODE_OUTPUT_PP;
  GPIO_InitStruct.Pull = GPIO_NOPULL;
  GPIO_InitStruct.Speed = GPIO_SPEED_FREQ_LOW;
  HAL_GPIO_Init(GPIOA, &GPIO_InitStruct);

}

void StartDefaultTask(void *argument)
{
  /* USER CODE BEGIN 5 */
  /* Infinite loop */
  for(;;)
  {
    osDelay(100);
  }
  /* USER CODE END 5 */
}

 /* MPU Configuration */

void MPU_Config(void)
{
  MPU_Region_InitTypeDef MPU_InitStruct = {0};

  /* Disables the MPU */
  HAL_MPU_Disable();

  /** Initializes and configures the Region and the memory to be protected
  */
  MPU_InitStruct.Enable = MPU_REGION_ENABLE;
  MPU_InitStruct.Number = MPU_REGION_NUMBER0;
  MPU_InitStruct.BaseAddress = 0x24000000;
  MPU_InitStruct.Size = MPU_REGION_SIZE_1MB;
  MPU_InitStruct.SubRegionDisable = 0x0;
  MPU_InitStruct.TypeExtField = MPU_TEX_LEVEL0;
  MPU_InitStruct.AccessPermission = MPU_REGION_FULL_ACCESS;
  MPU_InitStruct.DisableExec = MPU_INSTRUCTION_ACCESS_DISABLE;
  MPU_InitStruct.IsShareable = MPU_ACCESS_NOT_SHAREABLE;
  MPU_InitStruct.IsCacheable = MPU_ACCESS_CACHEABLE;
  MPU_InitStruct.IsBufferable = MPU_ACCESS_NOT_BUFFERABLE;

  HAL_MPU_ConfigRegion(&MPU_InitStruct);

  /** Initializes and configures the Region and the memory to be protected
  */
  MPU_InitStruct.Number = MPU_REGION_NUMBER1;
  MPU_InitStruct.BaseAddress = 0x90000000;
  MPU_InitStruct.Size = MPU_REGION_SIZE_512MB;
  MPU_InitStruct.AccessPermission = MPU_REGION_NO_ACCESS;
  MPU_InitStruct.IsCacheable = MPU_ACCESS_NOT_CACHEABLE;

  HAL_MPU_ConfigRegion(&MPU_InitStruct);

  /** Initializes and configures the Region and the memory to be protected
  */
  MPU_InitStruct.Number = MPU_REGION_NUMBER2;
  MPU_InitStruct.Size = MPU_REGION_SIZE_64MB;
  MPU_InitStruct.AccessPermission = MPU_REGION_FULL_ACCESS;
  MPU_InitStruct.IsCacheable = MPU_ACCESS_CACHEABLE;

  HAL_MPU_ConfigRegion(&MPU_InitStruct);

  /** Initializes and configures the Region and the memory to be protected
  */
  MPU_InitStruct.Number = MPU_REGION_NUMBER3;
  MPU_InitStruct.BaseAddress = 0xD0000000;
  MPU_InitStruct.Size = MPU_REGION_SIZE_512MB;
  MPU_InitStruct.AccessPermission = MPU_REGION_NO_ACCESS;
  MPU_InitStruct.IsCacheable = MPU_ACCESS_NOT_CACHEABLE;

  HAL_MPU_ConfigRegion(&MPU_InitStruct);

  /** Initializes and configures the Region and the memory to be protected
  */
  MPU_InitStruct.Number = MPU_REGION_NUMBER4;
  MPU_InitStruct.Size = MPU_REGION_SIZE_32MB;
  MPU_InitStruct.AccessPermission = MPU_REGION_FULL_ACCESS;
  MPU_InitStruct.IsCacheable = MPU_ACCESS_CACHEABLE;
  MPU_InitStruct.IsBufferable = MPU_ACCESS_BUFFERABLE;

  HAL_MPU_ConfigRegion(&MPU_InitStruct);
  /* Enables the MPU */
  HAL_MPU_Enable(MPU_PRIVILEGED_DEFAULT);

}

void HAL_TIM_PeriodElapsedCallback(TIM_HandleTypeDef *htim)
{
  if (htim->Instance == TIM6) {
    HAL_IncTick();
  }
}

void Error_Handler(void)
{
  __disable_irq();
  while (1)
  {
  }
}

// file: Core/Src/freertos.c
/* USER CODE BEGIN Header */
/**
  ******************************************************************************
  * File Name          : freertos.c
  * Description        : Code for freertos applications
  ******************************************************************************
  * @attention
  *
  * <h2><center>&copy; Copyright (c) 2021 STMicroelectronics.
  * All rights reserved.</center></h2>
  *
  * This software component is licensed by ST under Ultimate Liberty license
  * SLA0044, the "License"; You may not use this file except in compliance with
  * the License. You may obtain a copy of the License at:
  *                             www.st.com/SLA0044
  *
  ******************************************************************************
  */
/* USER CODE END Header */

#include "FreeRTOS.h"
#include "task.h"
#include "main.h"

/* USER CODE BEGIN FunctionPrototypes */
extern portBASE_TYPE IdleTaskHook(void* p);
/* USER CODE END FunctionPrototypes */

/* Hook prototypes */
void vApplicationIdleHook(void);

/* USER CODE BEGIN 2 */
void vApplicationIdleHook( void )
{
   /* vApplicationIdleHook() will only be called if configUSE_IDLE_HOOK is set
   to 1 in FreeRTOSConfig.h. It will be called on each iteration of the idle
   task. It is essential that code added to this hook function never attempts
   to block in any way (for example, call xQueueReceive() with a block time
   specified, or call vTaskDelay()). If the application makes use of the
   vTaskDelete() API function (as this demo application does) then it is also
   important that vApplicationIdleHook() is permitted to return to its calling
   function, because it is the responsibility of the idle task to clean up
   memory allocated by the kernel to any task that has since been deleted. */

  vTaskSetApplicationTaskTag(NULL, IdleTaskHook);
}
/* USER CODE END 2 */
